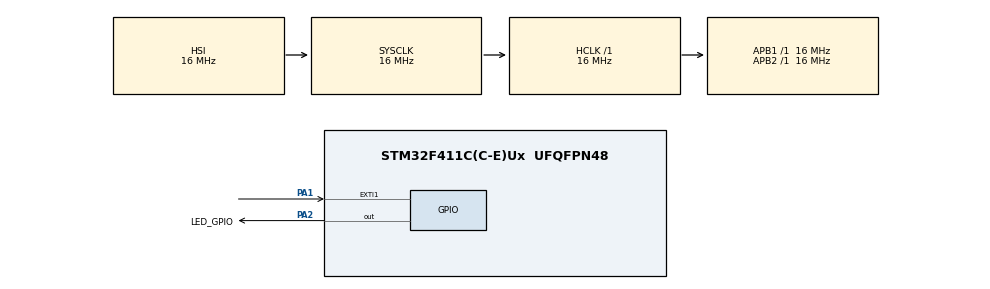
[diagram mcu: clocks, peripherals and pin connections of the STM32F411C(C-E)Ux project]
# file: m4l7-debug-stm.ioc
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FREERTOS.Tasks01=defaultTask,24,128,StartDefaultTask,Default,NULL,Dynamic,NULL,NULL;BlinkTask,24,128,StartBlinkTask,Default,NULL,Dynamic,NULL,NULL
FREERTOS.configUSE_NEWLIB_REENTRANT=1
FREERTOS.configUSE_PREEMPTION=0
Mcu.Family=STM32F4
Mcu.Name=STM32F411C(C-E)Ux
Mcu.Package=UFQFPN48
NVIC.EXTI1_IRQn=true\:0\:0\:false\:false\:true\:false\:true\:true\:true
NVIC.PriorityGroup=NVIC_PRIORITYGROUP_4
NVIC.TIM1_UP_TIM10_IRQn=true\:15\:0\:false\:false\:true\:false\:false\:true\:true
NVIC.TimeBase=TIM1_UP_TIM10_IRQn
NVIC.TimeBaseIP=TIM1
PA1.GPIO_ModeDefaultEXTI=GPIO_MODE_IT_FALLING
PA1.GPIO_PuPd=GPIO_PULLUP
PA1.Signal=GPXTI1
PA13.Mode=Serial_Wire
PA13.Signal=SYS_JTMS-SWDIO
PA14.Mode=Serial_Wire
PA14.Signal=SYS_JTCK-SWCLK
PA2.GPIO_Label=LED_GPIO
PA2.Signal=GPIO_Output
ProjectManager.HeapSize=0x200
ProjectManager.StackSize=0x400
ProjectManager.TargetToolchain=STM32CubeIDE
RCC.AHBFreq_Value=16000000
RCC.APB1Freq_Value=16000000
RCC.APB2Freq_Value=16000000
RCC.CortexFreq_Value=16000000
RCC.HSE_VALUE=25000000
RCC.HSI_VALUE=16000000
RCC.LSE_VALUE=32768
RCC.SYSCLKFreq_VALUE=16000000
RCC.VCOOutputFreq_Value=192000000
VP_FREERTOS_VS_CMSIS_V2.Mode=CMSIS_V2
VP_SYS_VS_tim1.Mode=TIM1
board=custom

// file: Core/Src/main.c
/* USER CODE BEGIN Header */
/**
  ******************************************************************************
  * @file           : main.c
  * @brief          : Main program body
  ******************************************************************************
  * @attention
  *
  * Copyright (c) 2026 STMicroelectronics.
  * All rights reserved.
  *
  * This software is licensed under terms that can be found in the LICENSE file
  * in the root directory of this software component.
  * If no LICENSE file comes with this software, it is provided AS-IS.
  *
  ******************************************************************************
  */
/* USER CODE END Header */
#include "main.h"
#include "cmsis_os.h"

/* USER CODE BEGIN Includes */
#include <stdio.h>

/* USER CODE END Includes */

/* Definitions for defaultTask */
osThreadId_t defaultTaskHandle;
const osThreadAttr_t defaultTask_attributes = {
  .name = "defaultTask",
  .stack_size = 128 * 4,
  .priority = (osPriority_t) osPriorityNormal,
};
/* Definitions for BlinkTask */
osThreadId_t BlinkTaskHandle;
const osThreadAttr_t BlinkTask_attributes = {
  .name = "BlinkTask",
  .stack_size = 128 * 4,
  .priority = (osPriority_t) osPriorityNormal,
};
/* USER CODE BEGIN PV */
volatile uint32_t blinkDelayMs = 500U;
static uint32_t randomState = 0xA341316CU;

/* USER CODE END PV */

void SystemClock_Config(void);
static void MX_GPIO_Init(void);
void StartDefaultTask(void *argument);
void StartBlinkTask(void *argument);

int main(void)
{

  /* MCU Configuration--------------------------------------------------------*/

  /* Reset of all peripherals, Initializes the Flash interface and the Systick. */
  HAL_Init();

  /* Configure the system clock */
  SystemClock_Config();

  /* Initialize all configured peripherals */
  MX_GPIO_Init();

  /* Init scheduler */
  osKernelInitialize();

  /* Create the thread(s) */
  /* creation of defaultTask */
  defaultTaskHandle = osThreadNew(StartDefaultTask, NULL, &defaultTask_attributes);

  /* creation of BlinkTask */
  BlinkTaskHandle = osThreadNew(StartBlinkTask, NULL, &BlinkTask_attributes);

  /* Start scheduler */
  osKernelStart();

  /* We should never get here as control is now taken by the scheduler */

  /* Infinite loop */
  while (1)
  {

  }
}

void SystemClock_Config(void)
{
  RCC_OscInitTypeDef RCC_OscInitStruct = {0};
  RCC_ClkInitTypeDef RCC_ClkInitStruct = {0};

  /** Configure the main internal regulator output voltage
  */
  __HAL_RCC_PWR_CLK_ENABLE();
  __HAL_PWR_VOLTAGESCALING_CONFIG(PWR_REGULATOR_VOLTAGE_SCALE1);

  /** Initializes the RCC Oscillators according to the specified parameters
  * in the RCC_OscInitTypeDef structure.
  */
  RCC_OscInitStruct.OscillatorType = RCC_OSCILLATORTYPE_HSI;
  RCC_OscInitStruct.HSIState = RCC_HSI_ON;
  RCC_OscInitStruct.HSICalibrationValue = RCC_HSICALIBRATION_DEFAULT;
  RCC_OscInitStruct.PLL.PLLState = RCC_PLL_NONE;
  if (HAL_RCC_OscConfig(&RCC_OscInitStruct) != HAL_OK)
  {
    Error_Handler();
  }

  /** Initializes the CPU, AHB and APB buses clocks
  */
  RCC_ClkInitStruct.ClockType = RCC_CLOCKTYPE_HCLK|RCC_CLOCKTYPE_SYSCLK
                              |RCC_CLOCKTYPE_PCLK1|RCC_CLOCKTYPE_PCLK2;
  RCC_ClkInitStruct.SYSCLKSource = RCC_SYSCLKSOURCE_HSI;
  RCC_ClkInitStruct.AHBCLKDivider = RCC_SYSCLK_DIV1;
  RCC_ClkInitStruct.APB1CLKDivider = RCC_HCLK_DIV1;
  RCC_ClkInitStruct.APB2CLKDivider = RCC_HCLK_DIV1;

  if (HAL_RCC_ClockConfig(&RCC_ClkInitStruct, FLASH_LATENCY_0) != HAL_OK)
  {
    Error_Handler();
  }
}

static void MX_GPIO_Init(void)
{
  GPIO_InitTypeDef GPIO_InitStruct = {0};

  /* GPIO Ports Clock Enable */
  __HAL_RCC_GPIOA_CLK_ENABLE();

  /*Configure GPIO pin Output Level */
  HAL_GPIO_WritePin(LED_GPIO_GPIO_Port, LED_GPIO_Pin, GPIO_PIN_RESET);

  /*Configure GPIO pin : PA1 */
  GPIO_InitStruct.Pin = GPIO_PIN_1;
  GPIO_InitStruct.Mode = GPIO_MODE_IT_FALLING;
  GPIO_InitStruct.Pull = GPIO_PULLUP;
  HAL_GPIO_Init(GPIOA, &GPIO_InitStruct);

  /*Configure GPIO pin : LED_GPIO_Pin */
  GPIO_InitStruct.Pin = LED_GPIO_Pin;
  GPIO_InitStruct.Mode = GPIO_MODE_OUTPUT_PP;
  GPIO_InitStruct.Pull = GPIO_NOPULL;
  GPIO_InitStruct.Speed = GPIO_SPEED_FREQ_LOW;
  HAL_GPIO_Init(LED_GPIO_GPIO_Port, &GPIO_InitStruct);

  /* EXTI interrupt init*/
  HAL_NVIC_SetPriority(EXTI1_IRQn, 0, 0);
  HAL_NVIC_EnableIRQ(EXTI1_IRQn);

}

/* USER CODE BEGIN 4 */
void HAL_GPIO_EXTI_Callback(uint16_t GPIO_Pin)
{
    if (GPIO_Pin == GPIO_PIN_1)
    {
      randomState ^= TIM1->CNT;
      randomState ^= randomState << 13;
      randomState ^= randomState >> 17;
      randomState ^= randomState << 5;
      blinkDelayMs = 100U + (randomState % 1901U);
    }
}
/* USER CODE END 4 */

void StartDefaultTask(void *argument)
{
  /* USER CODE BEGIN 5 */
  /* Infinite loop */
  for(;;)
  {
    printf("defaultTask is running\n");
    osDelay(2000);
  }
  /* USER CODE END 5 */
}

void StartBlinkTask(void *argument)
{
  /* USER CODE BEGIN StartBlinkTask */
  /* Infinite loop */
  for(;;)
  {
    GPIOA->ODR ^= GPIO_ODR_OD2;
    osDelay(blinkDelayMs);
  }
  /* USER CODE END StartBlinkTask */
}

void HAL_TIM_PeriodElapsedCallback(TIM_HandleTypeDef *htim)
{
  if (htim->Instance == TIM1)
  {
    HAL_IncTick();
  }
}

void Error_Handler(void)
{
  __disable_irq();
  while (1)
  {
  }
}
